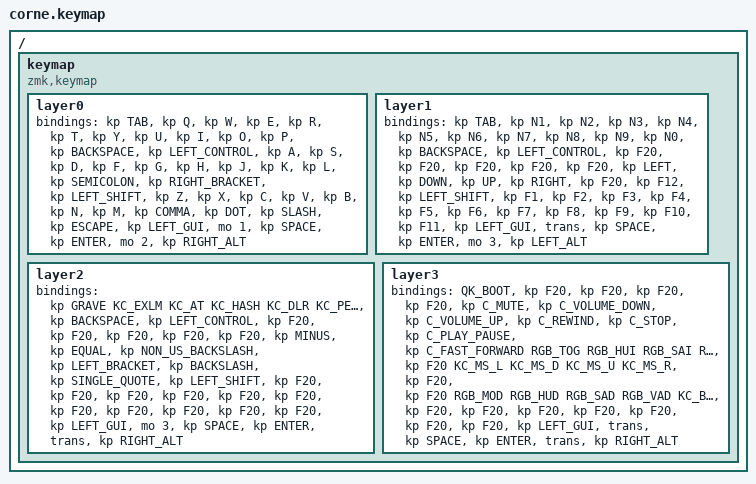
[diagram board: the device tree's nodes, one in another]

  /*
  * Copyright (c) 2020 The ZMK Contributors
  *
  * SPDX-License-Identifier: MIT
  */

  #include <behaviors.dtsi>
  #include <dt-bindings/zmk/keys.h>
  #include <dt-bindings/zmk/bt.h>
  #include <dt-bindings/zmk/ext_power.h>

  / {
    keymap {
      compatible = "zmk,keymap";
  layer0 {
          bindings = <
          &kp TAB &kp Q &kp W &kp E &kp R &kp T &kp Y &kp U &kp I &kp O &kp P &kp BACKSPACE &kp LEFT_CONTROL &kp A &kp S &kp D &kp F &kp G &kp H &kp J &kp K &kp L &kp SEMICOLON &kp RIGHT_BRACKET &kp LEFT_SHIFT &kp Z &kp X &kp C &kp V &kp B &kp N &kp M &kp COMMA &kp DOT &kp SLASH &kp ESCAPE &kp LEFT_GUI &mo 1 &kp SPACE &kp ENTER &mo 2 &kp RIGHT_ALT
          >;
        };layer1 {
          bindings = <
          &kp TAB &kp N1 &kp N2 &kp N3 &kp N4 &kp N5 &kp N6 &kp N7 &kp N8 &kp N9 &kp N0 &kp BACKSPACE &kp LEFT_CONTROL &kp F20 &kp F20 &kp F20 &kp F20 &kp F20 &kp LEFT &kp DOWN &kp UP &kp RIGHT &kp F20 &kp F12 &kp LEFT_SHIFT &kp F1 &kp F2 &kp F3 &kp F4 &kp F5 &kp F6 &kp F7 &kp F8 &kp F9 &kp F10 &kp F11 &kp LEFT_GUI &trans &kp SPACE &kp ENTER &mo 3 &kp LEFT_ALT
          >;
        };layer2 {
          bindings = <
          &kp GRAVE KC_EXLM KC_AT KC_HASH KC_DLR KC_PERC KC_CIRC KC_AMPR KC_ASTR KC_LPRN KC_RPRN &kp BACKSPACE &kp LEFT_CONTROL &kp F20 &kp F20 &kp F20 &kp F20 &kp F20 &kp MINUS &kp EQUAL &kp NON_US_BACKSLASH &kp LEFT_BRACKET &kp BACKSLASH &kp SINGLE_QUOTE &kp LEFT_SHIFT &kp F20 &kp F20 &kp F20 &kp F20 &kp F20 &kp F20 &kp F20 &kp F20 &kp F20 &kp F20 &kp F20 &kp LEFT_GUI &mo 3 &kp SPACE &kp ENTER &trans &kp RIGHT_ALT
          >;
        };layer3 {
          bindings = <
          QK_BOOT &kp F20 &kp F20 &kp F20 &kp F20 &kp C_MUTE &kp C_VOLUME_DOWN &kp C_VOLUME_UP &kp C_REWIND &kp C_STOP &kp C_PLAY_PAUSE &kp C_FAST_FORWARD RGB_TOG RGB_HUI RGB_SAI RGB_VAI KC_BTN1 &kp F20 KC_MS_L KC_MS_D KC_MS_U KC_MS_R &kp F20 &kp F20 RGB_MOD RGB_HUD RGB_SAD RGB_VAD KC_BTN2 &kp F20 &kp F20 &kp F20 &kp F20 &kp F20 &kp F20 &kp F20 &kp LEFT_GUI &trans &kp SPACE &kp ENTER &trans &kp RIGHT_ALT
          >;
        };
    };
  };
  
